# HC32M413 register map
File version: 1.0
CPU: CM4 r0p1, little endian, MPU, FPU, 4 interrupt priority bits
Registers are 32-bit, read-write, reset 0x0 unless marked. A register's access mark holds for its fields unless they carry their own. Offsets are from the block's base; [hi:lo] are bit positions; {n}, {i} and the like mark numbered series.

## FCM
Base 0x40048400
0x00 LVR
  [15:0] LVR
0x04 UVR
  [15:0] UVR
0x08 CNTR ro
  [15:0] CNTR
0x0C STR
  [0] START
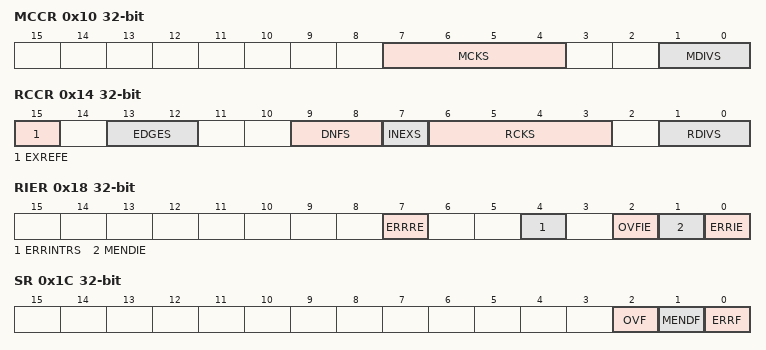
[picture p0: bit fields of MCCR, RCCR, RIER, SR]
0x10 MCCR
  [7:4] MCKS, [1:0] MDIVS
0x14 RCCR
  [15] EXREFE, [13:12] EDGES, [9:8] DNFS, [7] INEXS, [6:3] RCKS, [1:0] RDIVS
0x18 RIER
  [7] ERRRE, [4] ERRINTRS, [2] OVFIE, [1] MENDIE, [0] ERRIE
0x1C SR ro
  [2] OVF, [1] MENDF, [0] ERRF
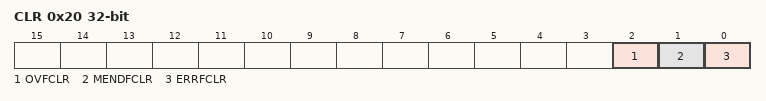
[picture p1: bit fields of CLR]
0x20 CLR wo
  [2] OVFCLR, [1] MENDFCLR, [0] ERRFCLR

## HALL
Base 0x4001E800
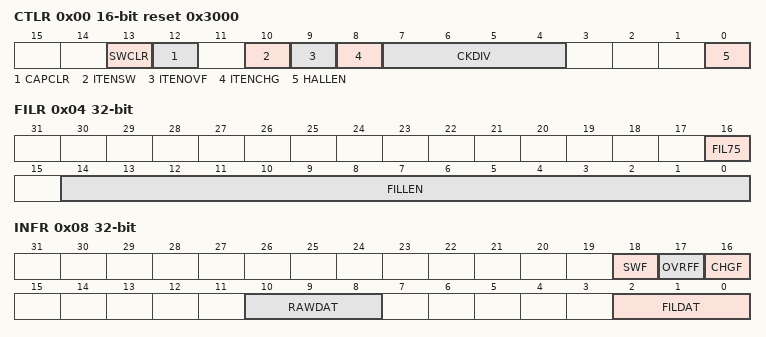
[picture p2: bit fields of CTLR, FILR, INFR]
0x00 CTLR 16-bit reset 0x3000
  [13] SWCLR, [12] CAPCLR, [10] ITENSW, [9] ITENOVF, [8] ITENCHG, [7:4] CKDIV, [0] HALLEN
0x04 FILR
  [16] FIL75, [14:0] FILLEN
0x08 INFR
  [18] SWF wo, [17] OVRFF, [16] CHGF, [10:8] RAWDAT ro, [2:0] FILDAT ro
0x10 CAPR ro
0x20 THDR reset 0xFFFFFFFF
0x30 CNTR

## I2C
Base 0x4004E000
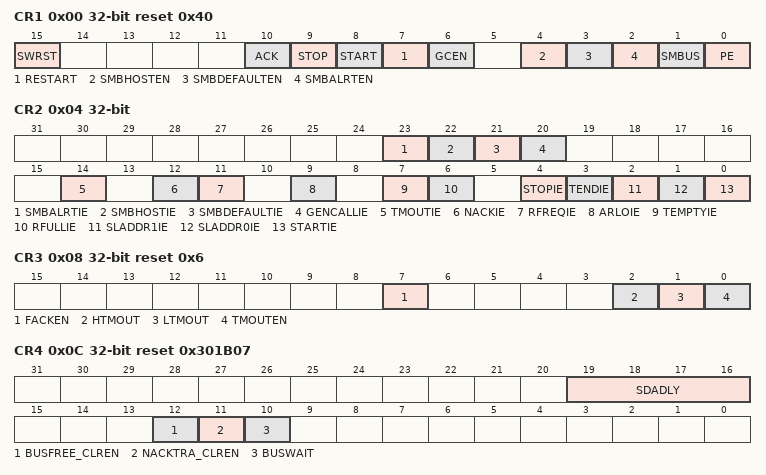
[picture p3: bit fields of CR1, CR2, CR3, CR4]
0x00 CR1 reset 0x40
  [15] SWRST, [10] ACK, [9] STOP, [8] START, [7] RESTART, [6] GCEN, [4] SMBHOSTEN, [3] SMBDEFAULTEN, [2] SMBALRTEN, [1] SMBUS, [0] PE
0x04 CR2
  [23] SMBALRTIE, [22] SMBHOSTIE, [21] SMBDEFAULTIE, [20] GENCALLIE, [14] TMOUTIE, [12] NACKIE, [11] RFREQIE, [9] ARLOIE, [7] TEMPTYIE, [6] RFULLIE, [4] STOPIE, [3] TENDIE, [2] SLADDR1IE, [1] SLADDR0IE, [0] STARTIE
0x08 CR3 reset 0x6
  [7] FACKEN, [2] HTMOUT, [1] LTMOUT, [0] TMOUTEN
0x0C CR4 reset 0x301B07
  [19:16] SDADLY, [12] BUSFREE_CLREN, [11] NACKTRA_CLREN, [10] BUSWAIT
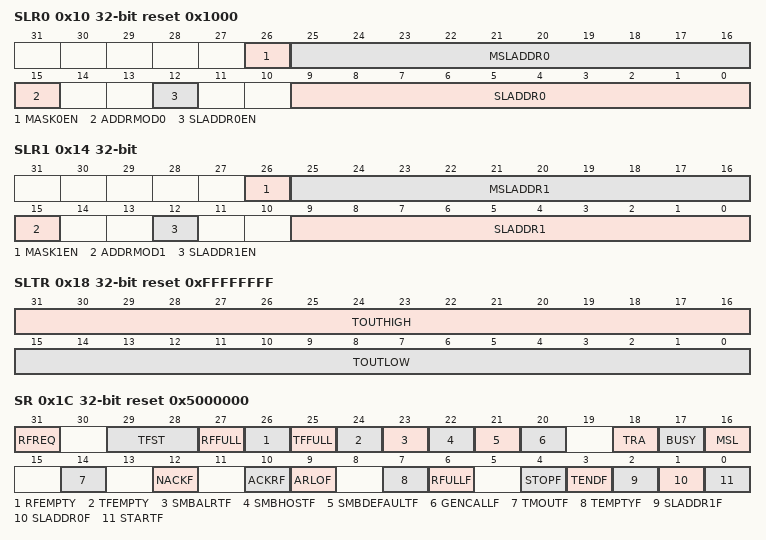
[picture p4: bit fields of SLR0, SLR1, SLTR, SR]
0x10 SLR0 reset 0x1000
  [26] MASK0EN, [25:16] MSLADDR0, [15] ADDRMOD0, [12] SLADDR0EN, [9:0] SLADDR0
0x14 SLR1
  [26] MASK1EN, [25:16] MSLADDR1, [15] ADDRMOD1, [12] SLADDR1EN, [9:0] SLADDR1
0x18 SLTR reset 0xFFFFFFFF
  [31:16] TOUTHIGH, [15:0] TOUTLOW
0x1C SR reset 0x5000000
  [31] RFREQ ro, [29:28] TFST ro, [27] RFFULL ro, [26] RFEMPTY ro, [25] TFFULL ro, [24] TFEMPTY ro, [23] SMBALRTF ro, [22] SMBHOSTF ro, [21] SMBDEFAULTF ro, [20] GENCALLF ro, [18] TRA, [17] BUSY ro, [16] MSL, [14] TMOUTF ro, [12] NACKF ro, [10] ACKRF ro, [9] ARLOF ro, [7] TEMPTYF ro, [6] RFULLF ro, [4] STOPF ro, [3] TENDF ro, [2] SLADDR1F ro, [1] SLADDR0F ro, [0] STARTF ro
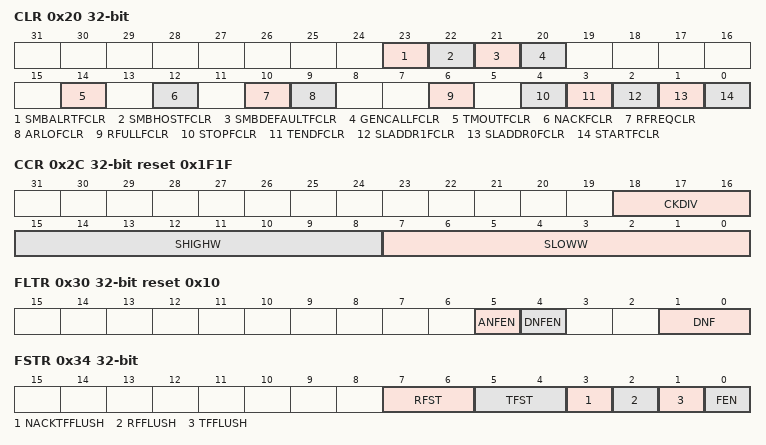
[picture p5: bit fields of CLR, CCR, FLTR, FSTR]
0x20 CLR wo
  [23] SMBALRTFCLR, [22] SMBHOSTFCLR, [21] SMBDEFAULTFCLR, [20] GENCALLFCLR, [14] TMOUTFCLR, [12] NACKFCLR, [10] RFREQCLR, [9] ARLOFCLR, [6] RFULLFCLR, [4] STOPFCLR, [3] TENDFCLR, [2] SLADDR1FCLR, [1] SLADDR0FCLR, [0] STARTFCLR
0x24 DTR 8-bit reset 0xFF
0x28 DRR 8-bit ro
0x2C CCR reset 0x1F1F
  [18:16] CKDIV, [15:8] SHIGHW, [7:0] SLOWW
0x30 FLTR reset 0x10
  [5] ANFEN, [4] DNFEN, [1:0] DNF
0x34 FSTR
  [7:6] RFST, [5:4] TFST, [3] NACKTFFLUSH, [2] RFFLUSH, [1] TFFLUSH, [0] FEN
0x38 SLVADDR
  [9:0] SLVADRR

## ICG
Base 0x00020000
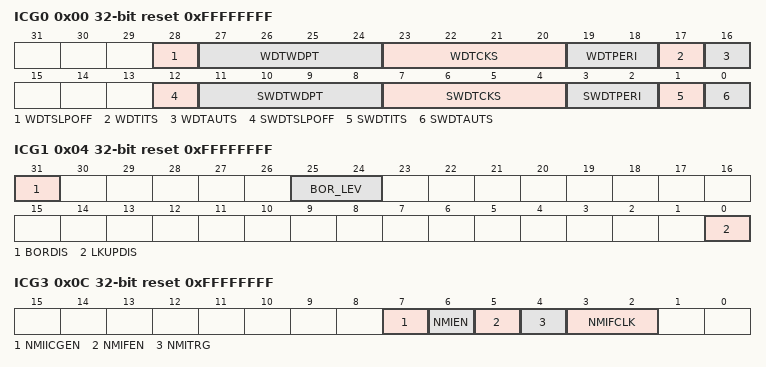
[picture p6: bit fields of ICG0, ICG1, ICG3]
0x00 ICG0 ro reset 0xFFFFFFFF
  [28] WDTSLPOFF, [27:24] WDTWDPT, [23:20] WDTCKS, [19:18] WDTPERI, [17] WDTITS, [16] WDTAUTS, [12] SWDTSLPOFF, [11:8] SWDTWDPT, [7:4] SWDTCKS, [3:2] SWDTPERI, [1] SWDTITS, [0] SWDTAUTS
0x04 ICG1 ro reset 0xFFFFFFFF
  [31] BORDIS, [25:24] BOR_LEV, [0] LKUPDIS
0x08 ICG2 ro reset 0xFFFFFFFF
  [2:0] HRCFREQSEL
0x0C ICG3 ro reset 0xFFFFFFFF
  [7] NMIICGEN, [6] NMIEN, [5] NMIFEN, [4] NMITRG, [3:2] NMIFCLK
0x10 ICG4 ro reset 0xFFFFFFFF

## INTC
Base 0x40051000
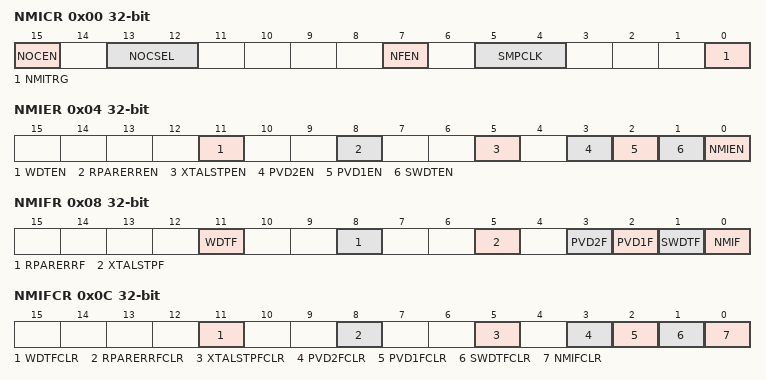
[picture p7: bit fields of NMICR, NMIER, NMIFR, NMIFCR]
0x00 NMICR
  [15] NOCEN, [13:12] NOCSEL, [7] NFEN, [5:4] SMPCLK, [0] NMITRG
0x04 NMIER
  [11] WDTEN, [8] RPARERREN, [5] XTALSTPEN, [3] PVD2EN, [2] PVD1EN, [1] SWDTEN, [0] NMIEN
0x08 NMIFR ro
  [11] WDTF, [8] RPARERRF, [5] XTALSTPF, [3] PVD2F, [2] PVD1F, [1] SWDTF, [0] NMIF
0x0C NMIFCR wo
  [11] WDTFCLR, [8] RPARERRFCLR, [5] XTALSTPFCLR, [3] PVD2FCLR, [2] PVD1FCLR, [1] SWDTFCLR, [0] NMIFCLR
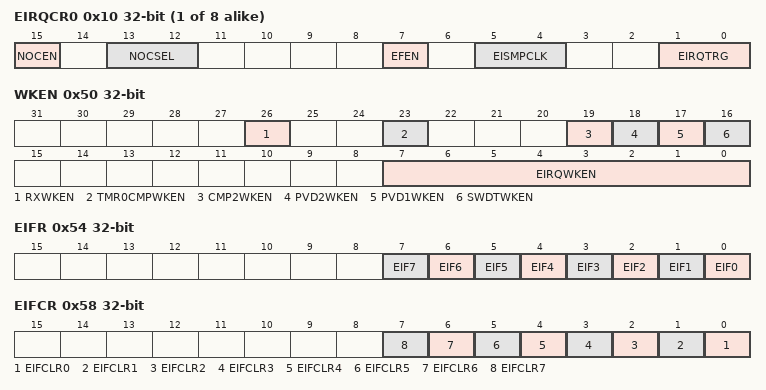
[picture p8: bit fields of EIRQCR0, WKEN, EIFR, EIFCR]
{0x10+4i} EIRQCR{i} (i=0..7)
  [15] NOCEN, [13:12] NOCSEL, [7] EFEN, [5:4] EISMPCLK, [1:0] EIRQTRG
0x50 WKEN
  [26] RXWKEN, [23] TMR0CMPWKEN, [19] CMP2WKEN, [18] PVD2WKEN, [17] PVD1WKEN, [16] SWDTWKEN, [7:0] EIRQWKEN
0x54 EIFR
  [n] EIF{n} (n=0..7)
0x58 EIFCR
  [n] EIFCLR{n} (n=0..7)
{0x5C+4i} INTSEL{i} reset 0x1FF (i=0..15)
  [8:0] INTSEL
{0x25C+4i} INTEN{i} reset 0xFFFFFFFF (i=0..15)
  [31:0] INTEN
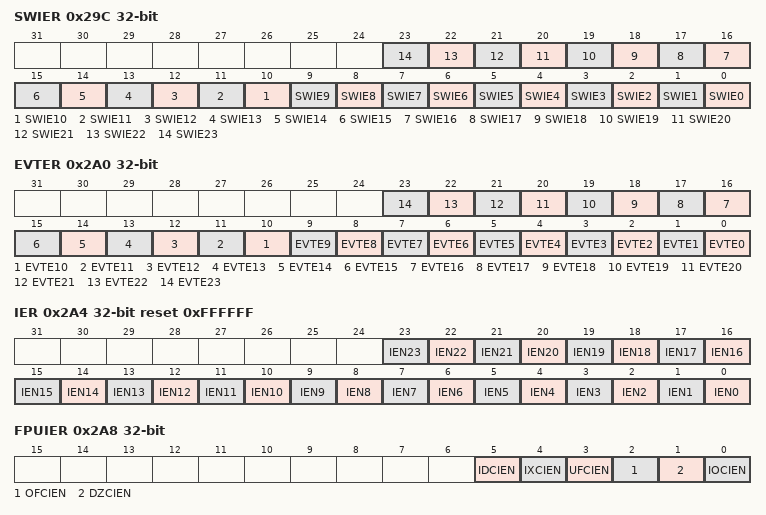
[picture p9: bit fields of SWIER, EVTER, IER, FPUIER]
0x29C SWIER
  [n] SWIE{n} (n=0..23)
0x2A0 EVTER
  [n] EVTE{n} (n=0..23)
0x2A4 IER reset 0xFFFFFF
  [n] IEN{n} (n=0..23)
0x2A8 FPUIER
  [5] IDCIEN, [4] IXCIEN, [3] UFCIEN, [2] OFCIEN, [1] DZCIEN, [0] IOCIEN
